VERSION ""

NS_ :

BS_:

BU_: DBG DRIVER IO MOTOR SENSOR

BO_ 100 DRIVER_HEARTBEAT: 1 DRIVER
 SG_ DRIVER_HEARTBEAT_cmd : 0|8@1+ (1,0) [0|0] "" SENSOR

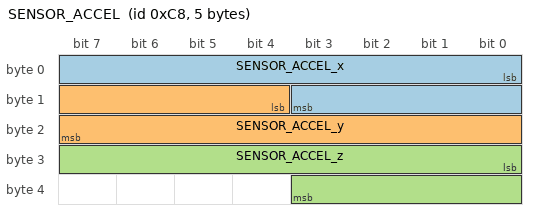
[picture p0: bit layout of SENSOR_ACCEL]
BO_ 200 SENSOR_ACCEL: 5 SENSOR
 SG_ SENSOR_ACCEL_x : 0|12@1+ (1,0) [0|0] "g" DRIVER
 SG_ SENSOR_ACCEL_y : 12|12@1+ (1,0) [0|0] "g" DRIVER
 SG_ SENSOR_ACCEL_z : 24|12@1+ (1,0) [0|0] "g" DRIVER

CM_ BU_ DRIVER "The driver controller";
CM_ BU_ SENSOR "The acceleration sensor controller on sjtwo board";

CM_ BO_ 100 "Sync message used to synchronize the controllers";
CM_ SG_ 100 DRIVER_HEARTBEAT_cmd "Heartbeat command from the driver";

BA_DEF_ "BusType" STRING ;
BA_DEF_ BO_ "GenMsgCycleTime" INT 0 0;
BA_DEF_ SG_ "FieldType" STRING ;

BA_DEF_DEF_ "BusType" "CAN";
BA_DEF_DEF_ "FieldType" "";
BA_DEF_DEF_ "GenMsgCycleTime" 0;

BA_ "GenMsgCycleTime" BO_ 100 1000;
BA_ "GenMsgCycleTime" BO_ 200 50;
BA_ "FieldType" SG_ 100 DRIVER_HEARTBEAT_cmd "DRIVER_HEARTBEAT_cmd";

VAL_ 100 DRIVER_HEARTBEAT_cmd 2 "DRIVER_HEARTBEAT_cmd_REBOOT" 1 "DRIVER_HEARTBEAT_cmd_SYNC" 0 "DRIVER_HEARTBEAT_cmd_NOOP" ;
